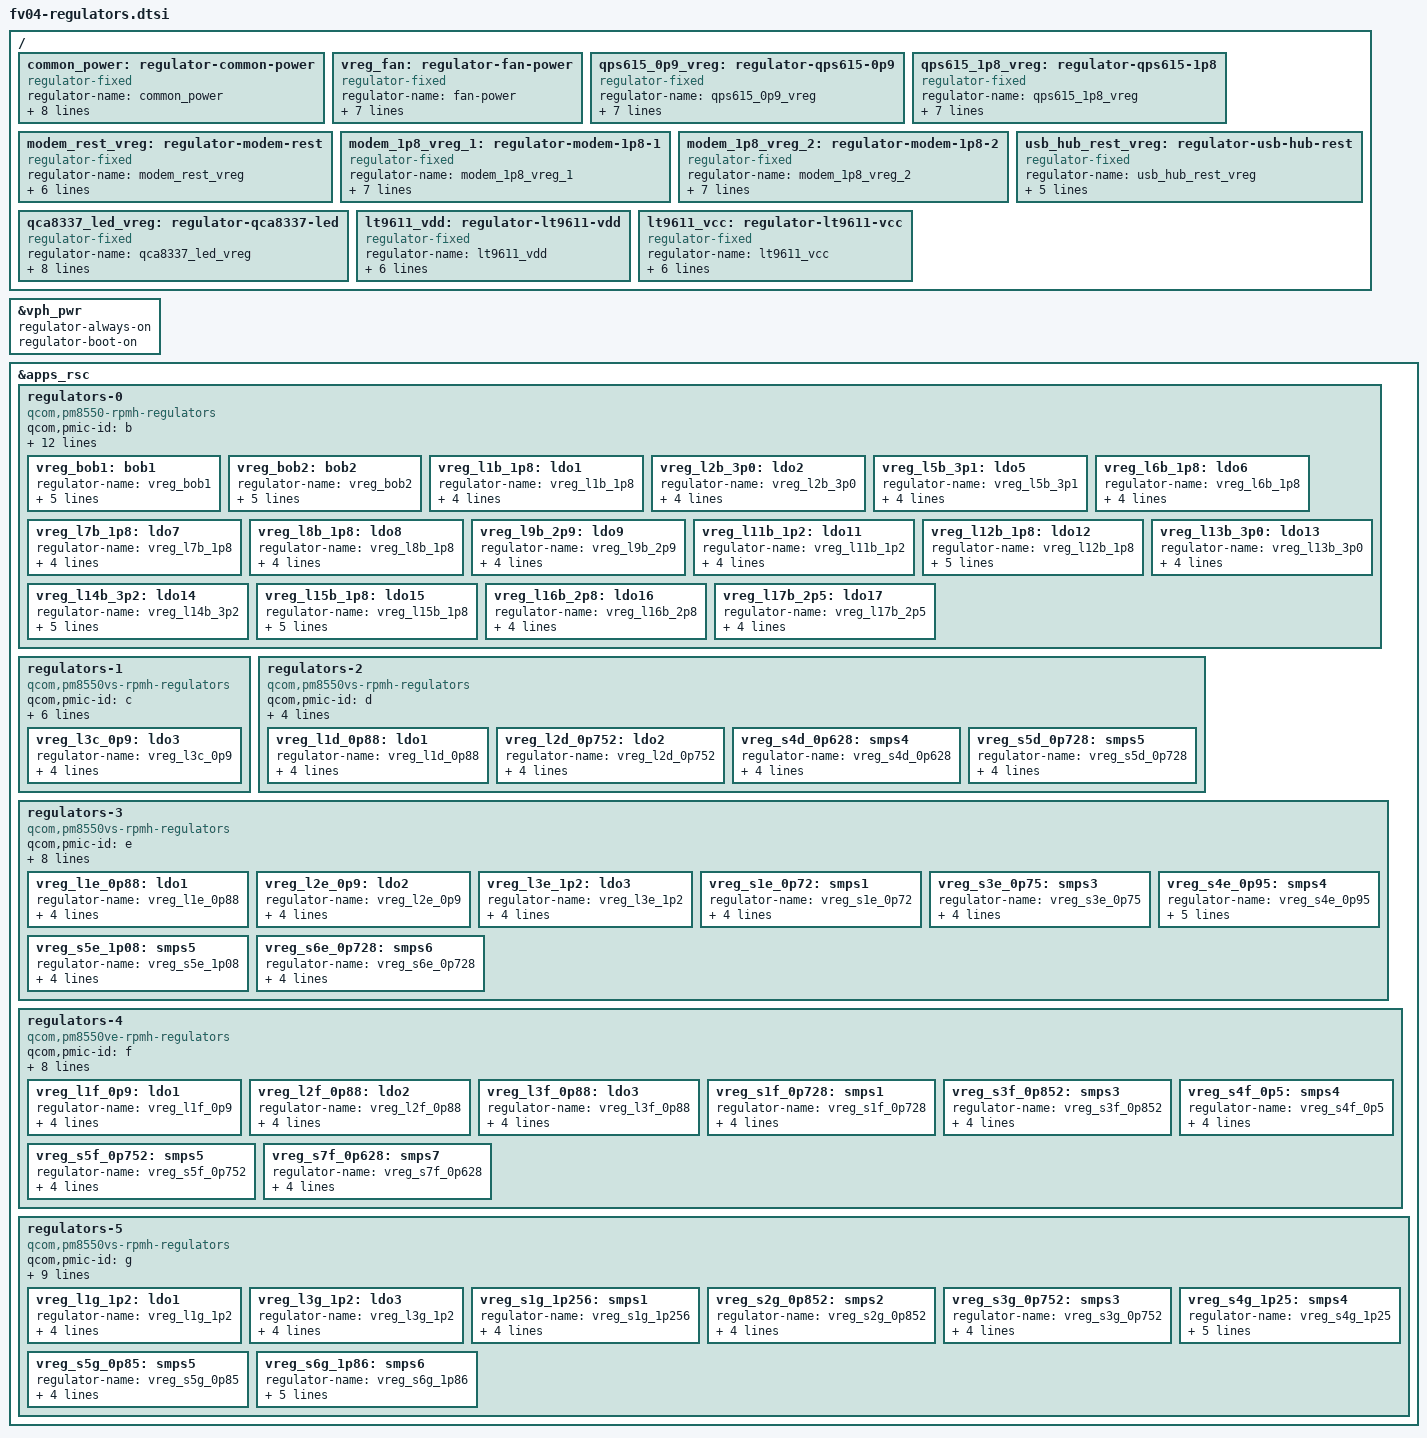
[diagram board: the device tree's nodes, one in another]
// SPDX-License-Identifier: BSD-3-Clause
/*
 * FV04 (A8550PF1 / QCS8550) carrier GPIO fixed-regulators and RPMh PMIC rails.
 *
 * Reconciled with live FV04 sysfs regulator states and factory-live-fdt.dts.
 * Note: PM8010 ("m", "n") and PMR735D are NOT populated on FV04 and are
 * intentionally omitted.
 */

&vph_pwr {
	regulator-always-on;
	regulator-boot-on;
};

/ {
	common_power: regulator-common-power {
		compatible = "regulator-fixed";
		regulator-name = "common_power";
		vin-supply = <&vph_pwr>;
		regulator-min-microvolt = <3300000>;
		regulator-max-microvolt = <3300000>;
		gpio = <&tlmm 10 GPIO_ACTIVE_HIGH>;
		enable-active-high;
		pinctrl-names = "default";
		pinctrl-0 = <&common_power_default>;
		regulator-boot-on;
		regulator-always-on;
	};

	vreg_fan: regulator-fan-power {
		compatible = "regulator-fixed";
		regulator-name = "fan-power";
		vin-supply = <&vph_pwr>;
		regulator-min-microvolt = <5000000>;
		regulator-max-microvolt = <5000000>;
		gpio = <&tlmm 43 GPIO_ACTIVE_HIGH>;
		enable-active-high;
		startup-delay-us = <10000>;
		pinctrl-names = "default";
		pinctrl-0 = <&fan_pwr_default>;
	};

	/*
	 * 6-stage carrier power/reset chain feeding PCIe1 (TC9563 switch,
	 * M.2 Key-M NVMe, Renesas uPD720201 USB3, and QCA8337 5x GbE).
	 */
	qps615_0p9_vreg: regulator-qps615-0p9 {
		compatible = "regulator-fixed";
		regulator-name = "qps615_0p9_vreg";
		vin-supply = <&common_power>;
		regulator-min-microvolt = <1000000>;
		regulator-max-microvolt = <1000000>;
		gpio = <&tlmm 34 GPIO_ACTIVE_HIGH>;
		enable-active-high;
		startup-delay-us = <4300>;
		pinctrl-names = "default";
		pinctrl-0 = <&qps615_0p9_default>;
	};

	qps615_1p8_vreg: regulator-qps615-1p8 {
		compatible = "regulator-fixed";
		regulator-name = "qps615_1p8_vreg";
		vin-supply = <&qps615_0p9_vreg>;
		regulator-min-microvolt = <1800000>;
		regulator-max-microvolt = <1800000>;
		gpio = <&tlmm 55 GPIO_ACTIVE_HIGH>;
		enable-active-high;
		startup-delay-us = <10000>;
		pinctrl-names = "default";
		pinctrl-0 = <&qps615_1p8_default>;
	};

	/* Active-low GPIO18 (no enable-active-high => driven LOW when enabled) */
	modem_rest_vreg: regulator-modem-rest {
		compatible = "regulator-fixed";
		regulator-name = "modem_rest_vreg";
		vin-supply = <&qps615_1p8_vreg>;
		regulator-min-microvolt = <3300000>;
		regulator-max-microvolt = <3300000>;
		gpio = <&tlmm 18 GPIO_ACTIVE_LOW>;
		startup-delay-us = <10000>;
		pinctrl-names = "default";
		pinctrl-0 = <&modem_rest_default>;
	};

	modem_1p8_vreg_1: regulator-modem-1p8-1 {
		compatible = "regulator-fixed";
		regulator-name = "modem_1p8_vreg_1";
		vin-supply = <&modem_rest_vreg>;
		regulator-min-microvolt = <1800000>;
		regulator-max-microvolt = <1800000>;
		gpio = <&tlmm 4 GPIO_ACTIVE_HIGH>;
		enable-active-high;
		startup-delay-us = <10000>;
		pinctrl-names = "default";
		pinctrl-0 = <&modem_1p8_1_default>;
	};

	modem_1p8_vreg_2: regulator-modem-1p8-2 {
		compatible = "regulator-fixed";
		regulator-name = "modem_1p8_vreg_2";
		vin-supply = <&modem_1p8_vreg_1>;
		regulator-min-microvolt = <1800000>;
		regulator-max-microvolt = <1800000>;
		gpio = <&tlmm 87 GPIO_ACTIVE_HIGH>;
		enable-active-high;
		startup-delay-us = <10000>;
		pinctrl-names = "default";
		pinctrl-0 = <&modem_1p8_2_default>;
	};

	/* Active-low GPIO2 (no enable-active-high => driven LOW when enabled) */
	usb_hub_rest_vreg: regulator-usb-hub-rest {
		compatible = "regulator-fixed";
		regulator-name = "usb_hub_rest_vreg";
		vin-supply = <&modem_1p8_vreg_2>;
		regulator-min-microvolt = <3300000>;
		regulator-max-microvolt = <3300000>;
		gpio = <&tlmm 2 GPIO_ACTIVE_LOW>;
		pinctrl-names = "default";
		pinctrl-0 = <&usb_hub_rest_default>;
	};

	qca8337_led_vreg: regulator-qca8337-led {
		compatible = "regulator-fixed";
		regulator-name = "qca8337_led_vreg";
		vin-supply = <&common_power>;
		regulator-min-microvolt = <1800000>;
		regulator-max-microvolt = <1800000>;
		gpio = <&tlmm 93 GPIO_ACTIVE_HIGH>;
		enable-active-high;
		pinctrl-names = "default";
		pinctrl-0 = <&qca8337_led_default>;
		regulator-boot-on;
		regulator-always-on;
	};

	lt9611_vdd: regulator-lt9611-vdd {
		compatible = "regulator-fixed";
		regulator-name = "lt9611_vdd";
		vin-supply = <&vph_pwr>;
		regulator-min-microvolt = <1200000>;
		regulator-max-microvolt = <1200000>;
		gpio = <&tlmm 13 GPIO_ACTIVE_HIGH>;
		enable-active-high;
		pinctrl-names = "default";
		pinctrl-0 = <&lt9611_1v8_default>;
	};

	lt9611_vcc: regulator-lt9611-vcc {
		compatible = "regulator-fixed";
		regulator-name = "lt9611_vcc";
		vin-supply = <&vph_pwr>;
		regulator-min-microvolt = <3300000>;
		regulator-max-microvolt = <3300000>;
		gpio = <&tlmm 52 GPIO_ACTIVE_HIGH>;
		enable-active-high;
		pinctrl-names = "default";
		pinctrl-0 = <&lt9611_3v3_default>;
	};
};

&apps_rsc {
	regulators-0 {
		compatible = "qcom,pm8550-rpmh-regulators";
		qcom,pmic-id = "b";

		vdd-bob1-supply = <&vph_pwr>;
		vdd-bob2-supply = <&vph_pwr>;
		vdd-l1-l4-l10-supply = <&vreg_s6g_1p86>;
		vdd-l2-l13-l14-supply = <&vreg_bob1>;
		vdd-l3-supply = <&vreg_s4g_1p25>;
		vdd-l5-l16-supply = <&vreg_bob1>;
		vdd-l6-l7-supply = <&vreg_bob1>;
		vdd-l8-l9-supply = <&vreg_bob1>;
		vdd-l11-supply = <&vreg_s4g_1p25>;
		vdd-l12-supply = <&vreg_s6g_1p86>;
		vdd-l15-supply = <&vreg_s6g_1p86>;
		vdd-l17-supply = <&vreg_bob2>;

		vreg_bob1: bob1 {
			regulator-name = "vreg_bob1";
			regulator-min-microvolt = <3296000>;
			regulator-max-microvolt = <3960000>;
			regulator-initial-mode = <RPMH_REGULATOR_MODE_HPM>;
			regulator-always-on;
		};

		vreg_bob2: bob2 {
			regulator-name = "vreg_bob2";
			regulator-min-microvolt = <2720000>;
			regulator-max-microvolt = <3960000>;
			regulator-initial-mode = <RPMH_REGULATOR_MODE_HPM>;
			regulator-always-on;
		};

		vreg_l1b_1p8: ldo1 {
			regulator-name = "vreg_l1b_1p8";
			regulator-min-microvolt = <1710000>;
			regulator-max-microvolt = <1950000>;
			regulator-initial-mode = <RPMH_REGULATOR_MODE_HPM>;
		};

		vreg_l2b_3p0: ldo2 {
			regulator-name = "vreg_l2b_3p0";
			regulator-min-microvolt = <2900000>;
			regulator-max-microvolt = <3544000>;
			regulator-initial-mode = <RPMH_REGULATOR_MODE_HPM>;
		};

		vreg_l5b_3p1: ldo5 {
			regulator-name = "vreg_l5b_3p1";
			regulator-min-microvolt = <3000000>;
			regulator-max-microvolt = <3300000>;
			regulator-initial-mode = <RPMH_REGULATOR_MODE_HPM>;
		};

		vreg_l6b_1p8: ldo6 {
			regulator-name = "vreg_l6b_1p8";
			regulator-min-microvolt = <1700000>;
			regulator-max-microvolt = <3300000>;
			regulator-initial-mode = <RPMH_REGULATOR_MODE_HPM>;
		};

		vreg_l7b_1p8: ldo7 {
			regulator-name = "vreg_l7b_1p8";
			regulator-min-microvolt = <1700000>;
			regulator-max-microvolt = <3300000>;
			regulator-initial-mode = <RPMH_REGULATOR_MODE_HPM>;
		};

		vreg_l8b_1p8: ldo8 {
			regulator-name = "vreg_l8b_1p8";
			regulator-min-microvolt = <1800000>;
			regulator-max-microvolt = <3008000>;
			regulator-initial-mode = <RPMH_REGULATOR_MODE_HPM>;
		};

		vreg_l9b_2p9: ldo9 {
			regulator-name = "vreg_l9b_2p9";
			regulator-min-microvolt = <2960000>;
			regulator-max-microvolt = <3008000>;
			regulator-initial-mode = <RPMH_REGULATOR_MODE_HPM>;
		};

		vreg_l11b_1p2: ldo11 {
			regulator-name = "vreg_l11b_1p2";
			regulator-min-microvolt = <1100000>;
			regulator-max-microvolt = <1300000>;
			regulator-initial-mode = <RPMH_REGULATOR_MODE_HPM>;
		};

		vreg_l12b_1p8: ldo12 {
			regulator-name = "vreg_l12b_1p8";
			regulator-min-microvolt = <1710000>;
			regulator-max-microvolt = <1950000>;
			regulator-initial-mode = <RPMH_REGULATOR_MODE_HPM>;
			regulator-always-on;
		};

		vreg_l13b_3p0: ldo13 {
			regulator-name = "vreg_l13b_3p0";
			regulator-min-microvolt = <2700000>;
			regulator-max-microvolt = <3300000>;
			regulator-initial-mode = <RPMH_REGULATOR_MODE_HPM>;
		};

		vreg_l14b_3p2: ldo14 {
			regulator-name = "vreg_l14b_3p2";
			regulator-min-microvolt = <3200000>;
			regulator-max-microvolt = <3300000>;
			regulator-initial-mode = <RPMH_REGULATOR_MODE_HPM>;
			regulator-always-on;
		};

		vreg_l15b_1p8: ldo15 {
			regulator-name = "vreg_l15b_1p8";
			regulator-min-microvolt = <1760000>;
			regulator-max-microvolt = <1800000>;
			regulator-initial-mode = <RPMH_REGULATOR_MODE_HPM>;
			regulator-always-on;
		};

		vreg_l16b_2p8: ldo16 {
			regulator-name = "vreg_l16b_2p8";
			regulator-min-microvolt = <2000000>;
			regulator-max-microvolt = <3400000>;
			regulator-initial-mode = <RPMH_REGULATOR_MODE_HPM>;
		};

		vreg_l17b_2p5: ldo17 {
			regulator-name = "vreg_l17b_2p5";
			regulator-min-microvolt = <2400000>;
			regulator-max-microvolt = <3300000>;
			regulator-initial-mode = <RPMH_REGULATOR_MODE_HPM>;
		};
	};

	regulators-1 {
		compatible = "qcom,pm8550vs-rpmh-regulators";
		qcom,pmic-id = "c";

		vdd-l1-supply = <&vreg_s4g_1p25>;
		vdd-l2-supply = <&vreg_s4e_0p95>;
		vdd-l3-supply = <&vreg_s4e_0p95>;
		vdd-s1-supply = <&vph_pwr>;
		vdd-s4-supply = <&vph_pwr>;
		vdd-s6-supply = <&vph_pwr>;

		vreg_l3c_0p9: ldo3 {
			regulator-name = "vreg_l3c_0p9";
			regulator-min-microvolt = <835000>;
			regulator-max-microvolt = <912000>;
			regulator-initial-mode = <RPMH_REGULATOR_MODE_HPM>;
		};
	};

	regulators-2 {
		compatible = "qcom,pm8550vs-rpmh-regulators";
		qcom,pmic-id = "d";

		vdd-l1-supply = <&vreg_s4e_0p95>;
		vdd-l2-supply = <&vreg_s4e_0p95>;
		vdd-s4-supply = <&vph_pwr>;
		vdd-s5-supply = <&vph_pwr>;

		vreg_l1d_0p88: ldo1 {
			regulator-name = "vreg_l1d_0p88";
			regulator-min-microvolt = <825000>;
			regulator-max-microvolt = <958000>;
			regulator-initial-mode = <RPMH_REGULATOR_MODE_HPM>;
		};

		vreg_l2d_0p752: ldo2 {
			regulator-name = "vreg_l2d_0p752";
			regulator-min-microvolt = <675000>;
			regulator-max-microvolt = <808000>;
			regulator-initial-mode = <RPMH_REGULATOR_MODE_HPM>;
		};

		vreg_s4d_0p628: smps4 {
			regulator-name = "vreg_s4d_0p628";
			regulator-min-microvolt = <572000>;
			regulator-max-microvolt = <988000>;
			regulator-initial-mode = <RPMH_REGULATOR_MODE_HPM>;
		};

		vreg_s5d_0p728: smps5 {
			regulator-name = "vreg_s5d_0p728";
			regulator-min-microvolt = <572000>;
			regulator-max-microvolt = <988000>;
			regulator-initial-mode = <RPMH_REGULATOR_MODE_HPM>;
		};
	};

	regulators-3 {
		compatible = "qcom,pm8550vs-rpmh-regulators";
		qcom,pmic-id = "e";

		vdd-l1-supply = <&vreg_s4e_0p95>;
		vdd-l2-supply = <&vreg_s4e_0p95>;
		vdd-l3-supply = <&vreg_s4g_1p25>;
		vdd-s1-supply = <&vph_pwr>;
		vdd-s3-supply = <&vph_pwr>;
		vdd-s4-supply = <&vph_pwr>;
		vdd-s5-supply = <&vph_pwr>;
		vdd-s6-supply = <&vph_pwr>;

		vreg_l1e_0p88: ldo1 {
			regulator-name = "vreg_l1e_0p88";
			regulator-min-microvolt = <831000>;
			regulator-max-microvolt = <904000>;
			regulator-initial-mode = <RPMH_REGULATOR_MODE_HPM>;
		};

		vreg_l2e_0p9: ldo2 {
			regulator-name = "vreg_l2e_0p9";
			regulator-min-microvolt = <870000>;
			regulator-max-microvolt = <970000>;
			regulator-initial-mode = <RPMH_REGULATOR_MODE_HPM>;
		};

		vreg_l3e_1p2: ldo3 {
			regulator-name = "vreg_l3e_1p2";
			regulator-min-microvolt = <1200000>;
			regulator-max-microvolt = <1200000>;
			regulator-initial-mode = <RPMH_REGULATOR_MODE_HPM>;
		};

		vreg_s1e_0p72: smps1 {
			regulator-name = "vreg_s1e_0p72";
			regulator-min-microvolt = <532000>;
			regulator-max-microvolt = <852000>;
			regulator-initial-mode = <RPMH_REGULATOR_MODE_HPM>;
		};

		vreg_s3e_0p75: smps3 {
			regulator-name = "vreg_s3e_0p75";
			regulator-min-microvolt = <716000>;
			regulator-max-microvolt = <884000>;
			regulator-initial-mode = <RPMH_REGULATOR_MODE_HPM>;
		};

		vreg_s4e_0p95: smps4 {
			regulator-name = "vreg_s4e_0p95";
			regulator-min-microvolt = <870100>;
			regulator-max-microvolt = <1152000>;
			regulator-initial-mode = <RPMH_REGULATOR_MODE_HPM>;
			regulator-always-on;
		};

		vreg_s5e_1p08: smps5 {
			regulator-name = "vreg_s5e_1p08";
			regulator-min-microvolt = <1010000>;
			regulator-max-microvolt = <1120000>;
			regulator-initial-mode = <RPMH_REGULATOR_MODE_HPM>;
		};

		vreg_s6e_0p728: smps6 {
			regulator-name = "vreg_s6e_0p728";
			regulator-min-microvolt = <528000>;
			regulator-max-microvolt = <904000>;
			regulator-initial-mode = <RPMH_REGULATOR_MODE_HPM>;
		};
	};

	regulators-4 {
		compatible = "qcom,pm8550ve-rpmh-regulators";
		qcom,pmic-id = "f";

		vdd-l1-supply = <&vreg_s4e_0p95>;
		vdd-l2-supply = <&vreg_s4e_0p95>;
		vdd-l3-supply = <&vreg_s4e_0p95>;
		vdd-s1-supply = <&vph_pwr>;
		vdd-s3-supply = <&vph_pwr>;
		vdd-s4-supply = <&vph_pwr>;
		vdd-s5-supply = <&vph_pwr>;
		vdd-s7-supply = <&vph_pwr>;

		vreg_l1f_0p9: ldo1 {
			regulator-name = "vreg_l1f_0p9";
			regulator-min-microvolt = <866000>;
			regulator-max-microvolt = <958000>;
			regulator-initial-mode = <RPMH_REGULATOR_MODE_HPM>;
		};

		vreg_l2f_0p88: ldo2 {
			regulator-name = "vreg_l2f_0p88";
			regulator-min-microvolt = <866000>;
			regulator-max-microvolt = <880000>;
			regulator-initial-mode = <RPMH_REGULATOR_MODE_HPM>;
		};

		vreg_l3f_0p88: ldo3 {
			regulator-name = "vreg_l3f_0p88";
			regulator-min-microvolt = <830000>;
			regulator-max-microvolt = <920000>;
			regulator-initial-mode = <RPMH_REGULATOR_MODE_HPM>;
		};

		vreg_s1f_0p728: smps1 {
			regulator-name = "vreg_s1f_0p728";
			regulator-min-microvolt = <516000>;
			regulator-max-microvolt = <904000>;
			regulator-initial-mode = <RPMH_REGULATOR_MODE_HPM>;
		};

		vreg_s3f_0p852: smps3 {
			regulator-name = "vreg_s3f_0p852";
			regulator-min-microvolt = <688000>;
			regulator-max-microvolt = <952000>;
			regulator-initial-mode = <RPMH_REGULATOR_MODE_HPM>;
		};

		vreg_s4f_0p5: smps4 {
			regulator-name = "vreg_s4f_0p5";
			regulator-min-microvolt = <300000>;
			regulator-max-microvolt = <500000>;
			regulator-initial-mode = <RPMH_REGULATOR_MODE_HPM>;
		};

		vreg_s5f_0p752: smps5 {
			regulator-name = "vreg_s5f_0p752";
			regulator-min-microvolt = <716000>;
			regulator-max-microvolt = <884000>;
			regulator-initial-mode = <RPMH_REGULATOR_MODE_HPM>;
		};

		vreg_s7f_0p628: smps7 {
			regulator-name = "vreg_s7f_0p628";
			regulator-min-microvolt = <516000>;
			regulator-max-microvolt = <812000>;
			regulator-initial-mode = <RPMH_REGULATOR_MODE_HPM>;
		};
	};

	regulators-5 {
		compatible = "qcom,pm8550vs-rpmh-regulators";
		qcom,pmic-id = "g";

		vdd-l1-supply = <&vreg_s4g_1p25>;
		vdd-l2-supply = <&vreg_s4g_1p25>;
		vdd-l3-supply = <&vreg_s4g_1p25>;
		vdd-s1-supply = <&vph_pwr>;
		vdd-s2-supply = <&vph_pwr>;
		vdd-s3-supply = <&vph_pwr>;
		vdd-s4-supply = <&vph_pwr>;
		vdd-s5-supply = <&vph_pwr>;
		vdd-s6-supply = <&vph_pwr>;

		vreg_l1g_1p2: ldo1 {
			regulator-name = "vreg_l1g_1p2";
			regulator-min-microvolt = <1140000>;
			regulator-max-microvolt = <1260000>;
			regulator-initial-mode = <RPMH_REGULATOR_MODE_HPM>;
		};

		vreg_l3g_1p2: ldo3 {
			regulator-name = "vreg_l3g_1p2";
			regulator-min-microvolt = <1200000>;
			regulator-max-microvolt = <1200000>;
			regulator-initial-mode = <RPMH_REGULATOR_MODE_HPM>;
		};

		vreg_s1g_1p256: smps1 {
			regulator-name = "vreg_s1g_1p256";
			regulator-min-microvolt = <1172000>;
			regulator-max-microvolt = <1388000>;
			regulator-initial-mode = <RPMH_REGULATOR_MODE_HPM>;
		};

		vreg_s2g_0p852: smps2 {
			regulator-name = "vreg_s2g_0p852";
			regulator-min-microvolt = <500000>;
			regulator-max-microvolt = <1053200>;
			regulator-initial-mode = <RPMH_REGULATOR_MODE_HPM>;
		};

		vreg_s3g_0p752: smps3 {
			regulator-name = "vreg_s3g_0p752";
			regulator-min-microvolt = <532000>;
			regulator-max-microvolt = <1148000>;
			regulator-initial-mode = <RPMH_REGULATOR_MODE_HPM>;
		};

		vreg_s4g_1p25: smps4 {
			regulator-name = "vreg_s4g_1p25";
			regulator-min-microvolt = <1172000>;
			regulator-max-microvolt = <1800000>;
			regulator-initial-mode = <RPMH_REGULATOR_MODE_HPM>;
			regulator-always-on;
		};

		vreg_s5g_0p85: smps5 {
			regulator-name = "vreg_s5g_0p85";
			regulator-min-microvolt = <800000>;
			regulator-max-microvolt = <1002600>;
			regulator-initial-mode = <RPMH_REGULATOR_MODE_HPM>;
		};

		vreg_s6g_1p86: smps6 {
			regulator-name = "vreg_s6g_1p86";
			regulator-min-microvolt = <1800000>;
			regulator-max-microvolt = <2192000>;
			regulator-initial-mode = <RPMH_REGULATOR_MODE_HPM>;
			regulator-always-on;
		};
	};
};
